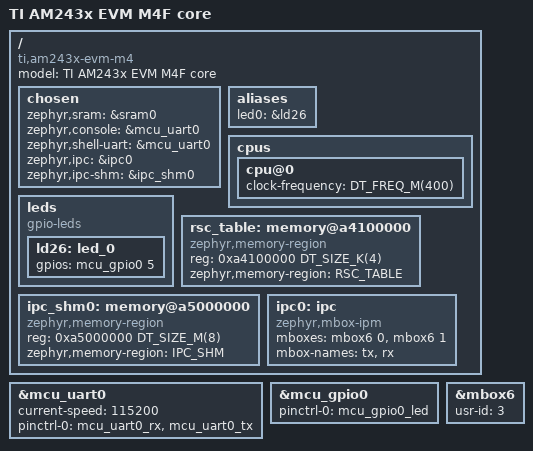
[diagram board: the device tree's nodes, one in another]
/*
 * Copyright (c) 2025 Texas Instruments Incorporated
 *
 * SPDX-License-Identifier: Apache-2.0
 */

/dts-v1/;

#include <zephyr/dt-bindings/gpio/gpio.h>
#include <ti/am64x_m4.dtsi>
#include "am243x_evm_am2434_m4-pinctrl.dtsi"

/ {
	model = "TI AM243x EVM M4F core";
	compatible = "ti,am243x-evm-m4";

	chosen {
		zephyr,sram = &sram0;
		zephyr,console = &mcu_uart0;
		zephyr,shell-uart = &mcu_uart0;
		zephyr,ipc = &ipc0;
		zephyr,ipc-shm = &ipc_shm0;
	};

	aliases {
		led0 = &ld26;
	};

	cpus {
		cpu@0 {
			status = "okay";
			clock-frequency = <DT_FREQ_M(400)>;
		};
	};

	leds: leds {
		compatible = "gpio-leds";

		ld26: led_0 {
			gpios = <&mcu_gpio0 5 GPIO_ACTIVE_HIGH>;
		};
	};

	rsc_table: memory@a4100000 {
		compatible = "zephyr,memory-region", "mmio-sram";
		reg = <0xa4100000 DT_SIZE_K(4)>;
		zephyr,memory-region = "RSC_TABLE";
	};

	ipc_shm0: memory@a5000000 {
		compatible = "zephyr,memory-region", "mmio-sram";
		reg = <0xa5000000 DT_SIZE_M(8)>;
		zephyr,memory-region = "IPC_SHM";
	};

	ipc0: ipc {
		compatible = "zephyr,mbox-ipm";
		mboxes = <&mbox6 0>, <&mbox6 1>;
		mbox-names = "tx", "rx";
	};
};

&mcu_uart0 {
	current-speed = <115200>;
	pinctrl-0 = <&mcu_uart0_rx &mcu_uart0_tx>;
	pinctrl-names = "default";
	status = "okay";
};

&mcu_gpio0 {
	pinctrl-0 = <&mcu_gpio0_led>;
	pinctrl-names = "default";
	status = "okay";
};

&mbox6 {
	usr-id = <3>;
	status = "okay";
};
